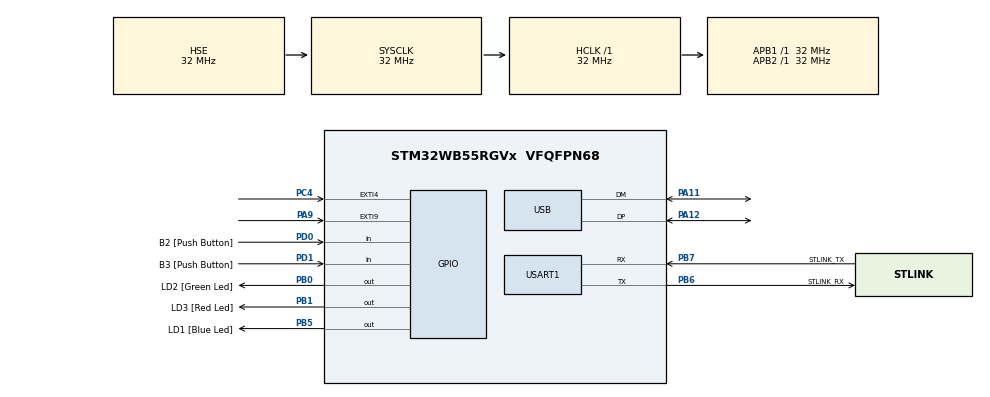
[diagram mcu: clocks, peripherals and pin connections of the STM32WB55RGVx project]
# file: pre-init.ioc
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Mcu.Family=STM32WB
Mcu.Name=STM32WB55RGVx
Mcu.Package=VFQFPN68
NVIC.EXTI4_IRQn=true\:0\:0\:false\:false\:true\:true\:true\:true
NVIC.EXTI9_5_IRQn=true\:0\:0\:false\:false\:true\:true\:true\:true
NVIC.PriorityGroup=NVIC_PRIORITYGROUP_4
OSC_IN.Mode=HSE-External-Oscillator
OSC_IN.Signal=RCC_OSC_IN
OSC_OUT.Mode=HSE-External-Oscillator
OSC_OUT.Signal=RCC_OSC_OUT
PA11.Mode=Device
PA11.Signal=USB_DM
PA12.Mode=Device
PA12.Signal=USB_DP
PA13.GPIO_Label=JTMS
PA13.Mode=Trace_Asynchronous_SW
PA13.Signal=SYS_JTMS-SWDIO
PA14.GPIO_Label=JTCK
PA14.Mode=Trace_Asynchronous_SW
PA14.Signal=SYS_JTCK-SWCLK
PA9.GPIO_ModeDefaultEXTI=GPIO_MODE_IT_FALLING
PA9.GPIO_PuPd=GPIO_PULLUP
PA9.Signal=GPXTI9
PB0.GPIO_Label=LD2 [Green Led]
PB0.Signal=GPIO_Output
PB1.GPIO_Label=LD3 [Red Led]
PB1.Signal=GPIO_Output
PB3.GPIO_Label=JTDO
PB3.Mode=Trace_Asynchronous_SW
PB3.Signal=SYS_JTDO-SWO
PB5.GPIO_Label=LD1 [Blue Led]
PB5.Signal=GPIO_Output
PB6.GPIO_Label=STLINK_RX
PB6.GPIO_PuPd=GPIO_PULLUP
PB6.Mode=Asynchronous
PB6.Signal=USART1_TX
PB7.GPIO_Label=STLINK_TX
PB7.GPIO_PuPd=GPIO_PULLUP
PB7.Mode=Asynchronous
PB7.Signal=USART1_RX
PC13.Mode=SYS_WakeUp1
PC13.Signal=SYS_WKUP2
PC14-OSC32_IN.Mode=LSE-External-Oscillator
PC14-OSC32_IN.Signal=RCC_OSC32_IN
PC15-OSC32_OUT.Mode=LSE-External-Oscillator
PC15-OSC32_OUT.Signal=RCC_OSC32_OUT
PC4.GPIO_ModeDefaultEXTI=GPIO_MODE_IT_RISING_FALLING
PC4.GPIO_PuPd=GPIO_PULLUP
PC4.Signal=GPXTI4
PD0.GPIO_Label=B2 [Push Button]
PD0.Signal=GPIO_Input
PD1.GPIO_Label=B3 [Push Button]
PD1.Signal=GPIO_Input
ProjectManager.HeapSize=0x200
ProjectManager.StackSize=0x400
ProjectManager.TargetToolchain=STM32CubeIDE
RCC.ADCFreq_Value=48000000
RCC.AHBFreq_Value=32000000
RCC.APB1Freq_Value=32000000
RCC.APB1TimFreq_Value=32000000
RCC.APB2Freq_Value=32000000
RCC.APB2TimFreq_Value=32000000
RCC.APB3Freq_Value=16000000
RCC.CortexFreq_Value=32000000
RCC.HCLKFreq_Value=32000000
RCC.HSE_VALUE=32000000
RCC.HSI48_VALUE=48000000
RCC.HSI_VALUE=16000000
RCC.LSE_Drive_Capability=RCC_LSEDRIVE_LOW
RCC.PLLN=32
RCC.PLLSAI1N=24
RCC.SMPSCLockSelectionVirtual=RCC_SMPSCLKSOURCE_HSI
RCC.SMPSCLockSelectionVirtualVirtual=RCC_SMPSCLKSOURCE_HSI
RCC.SMPSDivider=1
RCC.SYSCLKFreq_VALUE=32000000
RCC.SYSCLKSource=RCC_SYSCLKSOURCE_HSE
RCC.USBFreq_Value=48000000
RCC.VCOOutputFreq_Value=128000000
USART1.VirtualMode-Asynchronous=VM_ASYNC
USART1.WordLength=WORDLENGTH_7B
VP_MEMORYMAP_VS_MEMORYMAP.Mode=CurAppReg
board=NUCLEO-WB55RG

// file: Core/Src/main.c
/* USER CODE BEGIN Header */
/**
  ******************************************************************************
  * @file           : main.c
  * @brief          : Main program body
  ******************************************************************************
  * @attention
  *
  * Copyright (c) 2023 STMicroelectronics.
  * All rights reserved.
  *
  * This software is licensed under terms that can be found in the LICENSE file
  * in the root directory of this software component.
  * If no LICENSE file comes with this software, it is provided AS-IS.
  *
  ******************************************************************************
  */
/* USER CODE END Header */
#include "main.h"

UART_HandleTypeDef huart1;

PCD_HandleTypeDef hpcd_USB_FS;

void SystemClock_Config(void);
void PeriphCommonClock_Config(void);
static void MX_GPIO_Init(void);
static void MX_USART1_UART_Init(void);
static void MX_USB_PCD_Init(void);
static void MX_MEMORYMAP_Init(void);

int main(void)
{

  /* MCU Configuration--------------------------------------------------------*/

  /* Reset of all peripherals, Initializes the Flash interface and the Systick. */
  HAL_Init();

  /* Configure the system clock */
  SystemClock_Config();

/* Configure the peripherals common clocks */
  PeriphCommonClock_Config();

  /* Initialize all configured peripherals */
  MX_GPIO_Init();
  MX_USART1_UART_Init();
  MX_USB_PCD_Init();
  MX_MEMORYMAP_Init();

  /* Infinite loop */
  /* USER CODE BEGIN WHILE */
  while (1)
  {
	  //HAL_GPIO_WritePin(GPIOB,GPIO_PIN_1,0);
    /* USER CODE END WHILE */

  }
}

void SystemClock_Config(void)
{
  RCC_OscInitTypeDef RCC_OscInitStruct = {0};
  RCC_ClkInitTypeDef RCC_ClkInitStruct = {0};

  /** Macro to configure the PLL multiplication factor
  */
  __HAL_RCC_PLL_PLLM_CONFIG(RCC_PLLM_DIV1);

  /** Macro to configure the PLL clock source
  */
  __HAL_RCC_PLL_PLLSOURCE_CONFIG(RCC_PLLSOURCE_MSI);

  /** Configure LSE Drive Capability
  */
  HAL_PWR_EnableBkUpAccess();
  __HAL_RCC_LSEDRIVE_CONFIG(RCC_LSEDRIVE_LOW);

  /** Configure the main internal regulator output voltage
  */
  __HAL_PWR_VOLTAGESCALING_CONFIG(PWR_REGULATOR_VOLTAGE_SCALE1);

  /** Initializes the RCC Oscillators according to the specified parameters
  * in the RCC_OscInitTypeDef structure.
  */
  RCC_OscInitStruct.OscillatorType = RCC_OSCILLATORTYPE_HSI|RCC_OSCILLATORTYPE_HSE
                              |RCC_OSCILLATORTYPE_LSE|RCC_OSCILLATORTYPE_MSI;
  RCC_OscInitStruct.HSEState = RCC_HSE_ON;
  RCC_OscInitStruct.LSEState = RCC_LSE_ON;
  RCC_OscInitStruct.HSIState = RCC_HSI_ON;
  RCC_OscInitStruct.MSIState = RCC_MSI_ON;
  RCC_OscInitStruct.HSICalibrationValue = RCC_HSICALIBRATION_DEFAULT;
  RCC_OscInitStruct.MSICalibrationValue = RCC_MSICALIBRATION_DEFAULT;
  RCC_OscInitStruct.MSIClockRange = RCC_MSIRANGE_6;
  RCC_OscInitStruct.PLL.PLLState = RCC_PLL_NONE;
  if (HAL_RCC_OscConfig(&RCC_OscInitStruct) != HAL_OK)
  {
    Error_Handler();
  }

  /** Configure the SYSCLKSource, HCLK, PCLK1 and PCLK2 clocks dividers
  */
  RCC_ClkInitStruct.ClockType = RCC_CLOCKTYPE_HCLK4|RCC_CLOCKTYPE_HCLK2
                              |RCC_CLOCKTYPE_HCLK|RCC_CLOCKTYPE_SYSCLK
                              |RCC_CLOCKTYPE_PCLK1|RCC_CLOCKTYPE_PCLK2;
  RCC_ClkInitStruct.SYSCLKSource = RCC_SYSCLKSOURCE_HSE;
  RCC_ClkInitStruct.AHBCLKDivider = RCC_SYSCLK_DIV1;
  RCC_ClkInitStruct.APB1CLKDivider = RCC_HCLK_DIV1;
  RCC_ClkInitStruct.APB2CLKDivider = RCC_HCLK_DIV1;
  RCC_ClkInitStruct.AHBCLK2Divider = RCC_SYSCLK_DIV1;
  RCC_ClkInitStruct.AHBCLK4Divider = RCC_SYSCLK_DIV1;

  if (HAL_RCC_ClockConfig(&RCC_ClkInitStruct, FLASH_LATENCY_1) != HAL_OK)
  {
    Error_Handler();
  }

  /** Enable MSI Auto calibration
  */
  HAL_RCCEx_EnableMSIPLLMode();
}

void PeriphCommonClock_Config(void)
{
  RCC_PeriphCLKInitTypeDef PeriphClkInitStruct = {0};

  /** Initializes the peripherals clock
  */
  PeriphClkInitStruct.PeriphClockSelection = RCC_PERIPHCLK_SMPS;
  PeriphClkInitStruct.SmpsClockSelection = RCC_SMPSCLKSOURCE_HSI;
  PeriphClkInitStruct.SmpsDivSelection = RCC_SMPSCLKDIV_RANGE0;

  if (HAL_RCCEx_PeriphCLKConfig(&PeriphClkInitStruct) != HAL_OK)
  {
    Error_Handler();
  }
}

static void MX_MEMORYMAP_Init(void)
{

}

static void MX_USART1_UART_Init(void)
{

  huart1.Instance = USART1;
  huart1.Init.BaudRate = 115200;
  huart1.Init.WordLength = UART_WORDLENGTH_7B;
  huart1.Init.StopBits = UART_STOPBITS_1;
  huart1.Init.Parity = UART_PARITY_NONE;
  huart1.Init.Mode = UART_MODE_TX_RX;
  huart1.Init.HwFlowCtl = UART_HWCONTROL_NONE;
  huart1.Init.OverSampling = UART_OVERSAMPLING_16;
  huart1.Init.OneBitSampling = UART_ONE_BIT_SAMPLE_DISABLE;
  huart1.Init.ClockPrescaler = UART_PRESCALER_DIV1;
  huart1.AdvancedInit.AdvFeatureInit = UART_ADVFEATURE_NO_INIT;
  if (HAL_UART_Init(&huart1) != HAL_OK)
  {
    Error_Handler();
  }
  if (HAL_UARTEx_SetTxFifoThreshold(&huart1, UART_TXFIFO_THRESHOLD_1_8) != HAL_OK)
  {
    Error_Handler();
  }
  if (HAL_UARTEx_SetRxFifoThreshold(&huart1, UART_RXFIFO_THRESHOLD_1_8) != HAL_OK)
  {
    Error_Handler();
  }
  if (HAL_UARTEx_DisableFifoMode(&huart1) != HAL_OK)
  {
    Error_Handler();
  }

}

static void MX_USB_PCD_Init(void)
{

  hpcd_USB_FS.Instance = USB;
  hpcd_USB_FS.Init.dev_endpoints = 8;
  hpcd_USB_FS.Init.speed = PCD_SPEED_FULL;
  hpcd_USB_FS.Init.phy_itface = PCD_PHY_EMBEDDED;
  hpcd_USB_FS.Init.Sof_enable = DISABLE;
  hpcd_USB_FS.Init.low_power_enable = DISABLE;
  hpcd_USB_FS.Init.lpm_enable = DISABLE;
  hpcd_USB_FS.Init.battery_charging_enable = DISABLE;
  if (HAL_PCD_Init(&hpcd_USB_FS) != HAL_OK)
  {
    Error_Handler();
  }

}

static void MX_GPIO_Init(void)
{
  GPIO_InitTypeDef GPIO_InitStruct = {0};

  /* GPIO Ports Clock Enable */
  __HAL_RCC_GPIOC_CLK_ENABLE();
  __HAL_RCC_GPIOA_CLK_ENABLE();
  __HAL_RCC_GPIOB_CLK_ENABLE();
  __HAL_RCC_GPIOD_CLK_ENABLE();

  /*Configure GPIO pin Output Level */
  HAL_GPIO_WritePin(GPIOB, LD2_Pin|LD3_Pin|LD1_Pin, GPIO_PIN_RESET);

  /*Configure GPIO pin : PA9 */
  GPIO_InitStruct.Pin = GPIO_PIN_9;
  GPIO_InitStruct.Mode = GPIO_MODE_IT_FALLING;
  GPIO_InitStruct.Pull = GPIO_PULLUP;
  HAL_GPIO_Init(GPIOA, &GPIO_InitStruct);

  /*Configure GPIO pin : PC4 */
  GPIO_InitStruct.Pin = GPIO_PIN_4;
  GPIO_InitStruct.Mode = GPIO_MODE_IT_RISING_FALLING;
  GPIO_InitStruct.Pull = GPIO_PULLUP;
  HAL_GPIO_Init(GPIOC, &GPIO_InitStruct);

  /*Configure GPIO pins : LD2_Pin LD3_Pin LD1_Pin */
  GPIO_InitStruct.Pin = LD2_Pin|LD3_Pin|LD1_Pin;
  GPIO_InitStruct.Mode = GPIO_MODE_OUTPUT_PP;
  GPIO_InitStruct.Pull = GPIO_NOPULL;
  GPIO_InitStruct.Speed = GPIO_SPEED_FREQ_LOW;
  HAL_GPIO_Init(GPIOB, &GPIO_InitStruct);

  /*Configure GPIO pins : B2_Pin B3_Pin */
  GPIO_InitStruct.Pin = B2_Pin|B3_Pin;
  GPIO_InitStruct.Mode = GPIO_MODE_INPUT;
  GPIO_InitStruct.Pull = GPIO_NOPULL;
  HAL_GPIO_Init(GPIOD, &GPIO_InitStruct);

  /* EXTI interrupt init*/
  HAL_NVIC_SetPriority(EXTI4_IRQn, 0, 0);
  HAL_NVIC_EnableIRQ(EXTI4_IRQn);

  HAL_NVIC_SetPriority(EXTI9_5_IRQn, 0, 0);
  HAL_NVIC_EnableIRQ(EXTI9_5_IRQn);

}

void Error_Handler(void)
{
  __disable_irq();
  while (1)
  {
  }
}
